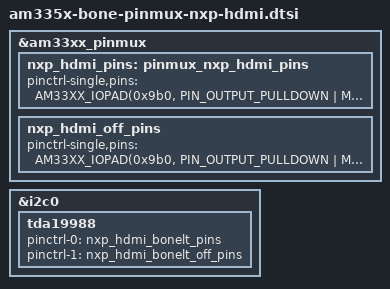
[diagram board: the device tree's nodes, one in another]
// SPDX-License-Identifier: GPL-2.0-only
/*
 * Copyright (C) 2012 Texas Instruments Incorporated - https://www.ti.com/
 */

#include "am335x-peripheral-nxp-hdmi.dtsi"

/* cape universal */

/*
 *&ocp {
 *	P8_27_pinmux {
 *		state = "disabled";
 *	};
 *	P8_28_pinmux {
 *		state = "disabled";
 *	};
 *	P8_29_pinmux {
 *		state = "disabled";
 *	};
 *	P8_30_pinmux {
 *		state = "disabled";
 *	};
 *	P8_31_pinmux {
 *		state = "disabled";
 *	};
 *	P8_32_pinmux {
 *		state = "disabled";
 *	};
 *	P8_33_pinmux {
 *		state = "disabled";
 *	};
 *	P8_34_pinmux {
 *		state = "disabled";
 *	};
 *	P8_35_pinmux {
 *		state = "disabled";
 *	};
 *	P8_36_pinmux {
 *		state = "disabled";
 *	};
 *	P8_37_pinmux {
 *		state = "disabled";
 *	};
 *	P8_38_pinmux {
 *		state = "disabled";
 *	};
 *	P8_39_pinmux {
 *		state = "disabled";
 *	};
 *	P8_40_pinmux {
 *		state = "disabled";
 *	};
 *	P8_41_pinmux {
 *		state = "disabled";
 *	};
 *	P8_42_pinmux {
 *		state = "disabled";
 *	};
 *	P8_43_pinmux {
 *		state = "disabled";
 *	};
 *	P8_44_pinmux {
 *		state = "disabled";
 *	};
 *	P8_45_pinmux {
 *		state = "disabled";
 *	};
 *	P8_46_pinmux {
 *		state = "disabled";
 *	};
 *};
 */

/* standard */

&am33xx_pinmux {
	nxp_hdmi_pins: pinmux_nxp_hdmi_pins {
		pinctrl-single,pins = <
			AM33XX_IOPAD(0x9b0, PIN_OUTPUT_PULLDOWN | MUX_MODE3)	/* xdma_event_intr0 */
			AM33XX_IOPAD(0x8a0, PIN_OUTPUT | MUX_MODE0)		/* lcd_data0.lcd_data0 */
			AM33XX_IOPAD(0x8a4, PIN_OUTPUT | MUX_MODE0)		/* lcd_data1.lcd_data1 */
			AM33XX_IOPAD(0x8a8, PIN_OUTPUT | MUX_MODE0)		/* lcd_data2.lcd_data2 */
			AM33XX_IOPAD(0x8ac, PIN_OUTPUT | MUX_MODE0)		/* lcd_data3.lcd_data3 */
			AM33XX_IOPAD(0x8b0, PIN_OUTPUT | MUX_MODE0)		/* lcd_data4.lcd_data4 */
			AM33XX_IOPAD(0x8b4, PIN_OUTPUT | MUX_MODE0)		/* lcd_data5.lcd_data5 */
			AM33XX_IOPAD(0x8b8, PIN_OUTPUT | MUX_MODE0)		/* lcd_data6.lcd_data6 */
			AM33XX_IOPAD(0x8bc, PIN_OUTPUT | MUX_MODE0)		/* lcd_data7.lcd_data7 */
			AM33XX_IOPAD(0x8c0, PIN_OUTPUT | MUX_MODE0)		/* lcd_data8.lcd_data8 */
			AM33XX_IOPAD(0x8c4, PIN_OUTPUT | MUX_MODE0)		/* lcd_data9.lcd_data9 */
			AM33XX_IOPAD(0x8c8, PIN_OUTPUT | MUX_MODE0)		/* lcd_data10.lcd_data10 */
			AM33XX_IOPAD(0x8cc, PIN_OUTPUT | MUX_MODE0)		/* lcd_data11.lcd_data11 */
			AM33XX_IOPAD(0x8d0, PIN_OUTPUT | MUX_MODE0)		/* lcd_data12.lcd_data12 */
			AM33XX_IOPAD(0x8d4, PIN_OUTPUT | MUX_MODE0)		/* lcd_data13.lcd_data13 */
			AM33XX_IOPAD(0x8d8, PIN_OUTPUT | MUX_MODE0)		/* lcd_data14.lcd_data14 */
			AM33XX_IOPAD(0x8dc, PIN_OUTPUT | MUX_MODE0)		/* lcd_data15.lcd_data15 */
			AM33XX_IOPAD(0x8e0, PIN_OUTPUT_PULLDOWN | MUX_MODE0)	/* lcd_vsync.lcd_vsync */
			AM33XX_IOPAD(0x8e4, PIN_OUTPUT_PULLDOWN | MUX_MODE0)	/* lcd_hsync.lcd_hsync */
			AM33XX_IOPAD(0x8e8, PIN_OUTPUT_PULLDOWN | MUX_MODE0)	/* lcd_pclk.lcd_pclk */
			AM33XX_IOPAD(0x8ec, PIN_OUTPUT_PULLDOWN | MUX_MODE0)	/* lcd_ac_bias_en.lcd_ac_bias_en */
		>;
	};

	nxp_hdmi_off_pins: nxp_hdmi_off_pins {
		pinctrl-single,pins = <
			AM33XX_IOPAD(0x9b0, PIN_OUTPUT_PULLDOWN | MUX_MODE3)	/* xdma_event_intr0 */
		>;
	};
};

&i2c0 {
	tda19988 {
		pinctrl-names = "default", "off";
		pinctrl-0 = <&nxp_hdmi_bonelt_pins>;
		pinctrl-1 = <&nxp_hdmi_bonelt_off_pins>;
	};
};
